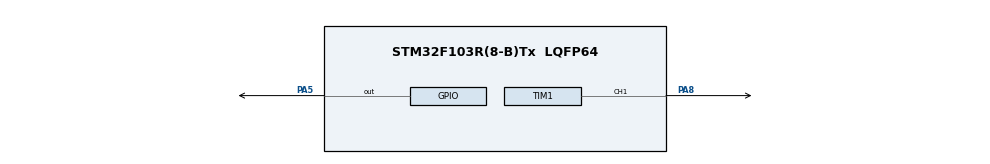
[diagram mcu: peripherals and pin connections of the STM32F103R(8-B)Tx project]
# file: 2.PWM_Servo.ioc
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Mcu.Family=STM32F1
Mcu.Name=STM32F103R(8-B)Tx
Mcu.Package=LQFP64
NVIC.PriorityGroup=NVIC_PRIORITYGROUP_4
NVIC.TIM1_CC_IRQn=true\:0\:0\:false\:false\:true\:true\:true\:true
NVIC.TIM1_UP_IRQn=true\:0\:0\:false\:false\:true\:true\:true\:true
PA5.PinState=GPIO_PIN_RESET
PA5.Signal=GPIO_Output
PA8.Signal=S_TIM1_CH1
PD0-OSC_IN.Mode=HSE-External-Oscillator
PD0-OSC_IN.Signal=RCC_OSC_IN
PD1-OSC_OUT.Mode=HSE-External-Oscillator
PD1-OSC_OUT.Signal=RCC_OSC_OUT
ProjectManager.HeapSize=0x200
ProjectManager.StackSize=0x400
ProjectManager.TargetToolchain=STM32CubeIDE
RCC.APB1Freq_Value=8000000
RCC.APB2Freq_Value=8000000
SH.S_TIM1_CH1.0=TIM1_CH1,PWM Generation1 CH1
TIM1.Channel-PWM\ Generation1\ CH1=TIM_CHANNEL_1
TIM1.Period=10000-1
TIM1.Prescaler=8-1
TIM1.Pulse-PWM\ Generation1\ CH1=5000-1
VP_SYS_VS_ND.Mode=No_Debug
VP_TIM1_VS_ClockSourceINT.Mode=Internal
board=custom

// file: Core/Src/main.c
/* USER CODE BEGIN Header */
/**
  ******************************************************************************
  * @file           : main.c
  * @brief          : Main program body
  ******************************************************************************
  * @attention
  *
  * Copyright (c) 2024 STMicroelectronics.
  * All rights reserved.
  *
  * This software is licensed under terms that can be found in the LICENSE file
  * in the root directory of this software component.
  * If no LICENSE file comes with this software, it is provided AS-IS.
  *
  ******************************************************************************
  */
/* USER CODE END Header */
#include "main.h"
#include "tim.h"
#include "gpio.h"

/* USER CODE BEGIN PD */
typedef struct ServoInfo
{
	GPIO_PinState 	enumPinServo;

	uint32_t 		iTIM1ARR;
	uint32_t 		iServoCCR;
	uint32_t 		iServoDuty;
}ServoInfo;

/* USER CODE END PD */

/* USER CODE BEGIN PV */
uint32_t iDuty = 0;
ServoInfo gServoInfo = {0,0,0};
/* USER CODE END PV */

void SystemClock_Config(void);

/* USER CODE BEGIN 0 */
void SetServoDuty(const uint32_t iDuty)
{
	// 2024-10-28 hjkim, Calculate the new CCR value and set it for TIM1 Channel 1
	uint32_t newCCR = (iDuty * gServoInfo.iTIM1ARR) / 100;

    __HAL_TIM_SET_COMPARE(&htim1, TIM_CHANNEL_1, newCCR);

	// 2024-10-28 hjkim, Update Servo Information
    gServoInfo.iServoCCR 	= __HAL_TIM_GET_COMPARE(&htim1, TIM_CHANNEL_1);
	gServoInfo.iTIM1ARR 	= __HAL_TIM_GET_AUTORELOAD(&htim1);
    gServoInfo.iServoDuty 	= iDuty;

	// 2024-10-28 hjkim, Handle case where duty is 0 (reset pin to Low)
    gServoInfo.enumPinServo = (iDuty == 0) ? GPIO_PIN_RESET : gServoInfo.enumPinServo;

    // 2024-10-28 hjkim, Set GPIO A5 pin based on duty cycle (Low if duty is 0, otherwise keep current state)
    if(gServoInfo.enumPinServo == GPIO_PIN_RESET)
    {
    	HAL_GPIO_WritePin(GPIOA, GPIO_PIN_5, gServoInfo.enumPinServo);
    }

	// 2024-10-28 hjkim, Retrieve duty cycle using HAL macros, this method is recommended
	//gServoInfo.iServoCCR 	= __HAL_TIM_GET_COMPARE(&htim1, TIM_CHANNEL_1);
	//gServoInfo.iTIM1ARR 	= __HAL_TIM_GET_AUTORELOAD(&htim1);
	//gServoInfo.iServoDuty 	= (ccr_value * 100) / arr_value;

	// 2024-10-28 hjkim, Retrieve duty cycle directly from register
	//uint32_t duty_cycle2	= (TIM1->CCR1 *100) / TIM1->ARR;

	return;
}
/* USER CODE END 0 */

int main(void)
{

  /* MCU Configuration--------------------------------------------------------*/

  /* Reset of all peripherals, Initializes the Flash interface and the Systick. */
  HAL_Init();

  /* Configure the system clock */
  SystemClock_Config();

  /* Initialize all configured peripherals */
  MX_GPIO_Init();
  MX_TIM1_Init();
  /* USER CODE BEGIN 2 */
  // 2024-10-28 hjkim, For HAL_TIM_PWM_PulseFinishedCallback: Start the base timer interrupt
  HAL_TIM_Base_Start_IT(&htim1);
  // 2024-10-28 hjkim, For HAL_TIM_PeriodElapsedCallback: Start the PWM interrupt for TIM1 Channel 1
  HAL_TIM_PWM_Start_IT(&htim1, TIM_CHANNEL_1);
  /* USER CODE END 2 */

  /* Infinite loop */
  while (1)
  {

    /* USER CODE BEGIN 3 */
	SetServoDuty(iDuty);
  }
  /* USER CODE END 3 */
}

void SystemClock_Config(void)
{
  RCC_OscInitTypeDef RCC_OscInitStruct = {0};
  RCC_ClkInitTypeDef RCC_ClkInitStruct = {0};

  /** Initializes the RCC Oscillators according to the specified parameters
  * in the RCC_OscInitTypeDef structure.
  */
  RCC_OscInitStruct.OscillatorType = RCC_OSCILLATORTYPE_HSI;
  RCC_OscInitStruct.HSIState = RCC_HSI_ON;
  RCC_OscInitStruct.HSICalibrationValue = RCC_HSICALIBRATION_DEFAULT;
  RCC_OscInitStruct.PLL.PLLState = RCC_PLL_NONE;
  if (HAL_RCC_OscConfig(&RCC_OscInitStruct) != HAL_OK)
  {
    Error_Handler();
  }

  /** Initializes the CPU, AHB and APB buses clocks
  */
  RCC_ClkInitStruct.ClockType = RCC_CLOCKTYPE_HCLK|RCC_CLOCKTYPE_SYSCLK
                              |RCC_CLOCKTYPE_PCLK1|RCC_CLOCKTYPE_PCLK2;
  RCC_ClkInitStruct.SYSCLKSource = RCC_SYSCLKSOURCE_HSI;
  RCC_ClkInitStruct.AHBCLKDivider = RCC_SYSCLK_DIV1;
  RCC_ClkInitStruct.APB1CLKDivider = RCC_HCLK_DIV1;
  RCC_ClkInitStruct.APB2CLKDivider = RCC_HCLK_DIV1;

  if (HAL_RCC_ClockConfig(&RCC_ClkInitStruct, FLASH_LATENCY_0) != HAL_OK)
  {
    Error_Handler();
  }
}
/* USER CODE BEGIN 4 */
void HAL_TIM_PeriodElapsedCallback(TIM_HandleTypeDef *htim)
{
    // 2024-10-28 hjkim, Select Timer
    if (htim->Instance == TIM1)
    {
        // 2024-10-28 hjkim, Toggle GPIO pin A5 for Channel 1
        gServoInfo.enumPinServo = GPIO_PIN_SET;
        HAL_GPIO_WritePin(GPIOA, GPIO_PIN_5, gServoInfo.enumPinServo);
    }
    else if (htim->Instance == TIM2)
    {
        // 2024-10-28 hjkim, Error: TIM2 is not used
        __NOP();
    }
    else if (htim->Instance == TIM3)
    {
        // 2024-10-28 hjkim, Error: TIM3 is not used
        __NOP();
    }
    else if (htim->Instance == TIM4)
    {
        // 2024-10-28 hjkim, Error: TIM4 is not used
        __NOP();
    }
    else
    {
        // 2024-10-28 hjkim, Error: Invalid channel
        __NOP();
    }

    return;
}
void HAL_TIM_PWM_PulseFinishedCallback(TIM_HandleTypeDef *htim)
{
	// 2024-10-28 hjkim, Select Timer & Channel
	    if(htim->Instance == TIM1)
	    {
	        switch (htim->Channel)
	        {
	            case HAL_TIM_ACTIVE_CHANNEL_1:
	            	gServoInfo.enumPinServo = GPIO_PIN_RESET;
	            	HAL_GPIO_WritePin(GPIOA, GPIO_PIN_5, gServoInfo.enumPinServo);
	                break;
	            case HAL_TIM_ACTIVE_CHANNEL_2:
	                // 2024-10-28 hjkim, Error: Channel 2 is not used
	                __NOP();
	                break;
	            case HAL_TIM_ACTIVE_CHANNEL_3:
	                // 2024-10-28 hjkim, Error: Channel 3 is not used
	                __NOP();
	                break;
	            case HAL_TIM_ACTIVE_CHANNEL_4:
	                // 2024-10-28 hjkim, Error: Channel 4 is not used
	                __NOP();
	                break;
	            default:
	                // 2024-10-28 hjkim, Error: Invalid channel
	                __NOP();
	                break;
	        }
	    }
}
/* USER CODE END 4 */
void Error_Handler(void)
{
  __disable_irq();
  while (1)
  {
  }
}
